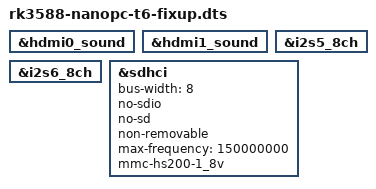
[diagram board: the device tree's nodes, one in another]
// SPDX-License-Identifier: (GPL-2.0+ OR MIT)

#include "rk3588-nanopc-t6.dts"

&hdmi0_sound {
 	status = "okay";
};

&hdmi1_sound {
	status = "okay";
};

&i2s5_8ch {
 	status = "okay";
};

&i2s6_8ch {
	status = "okay";
};

&sdhci {
        bus-width = <8>;
        no-sdio;
        no-sd;
        non-removable;
        max-frequency = <150000000>;
        mmc-hs200-1_8v;
        status = "okay";
};                      
